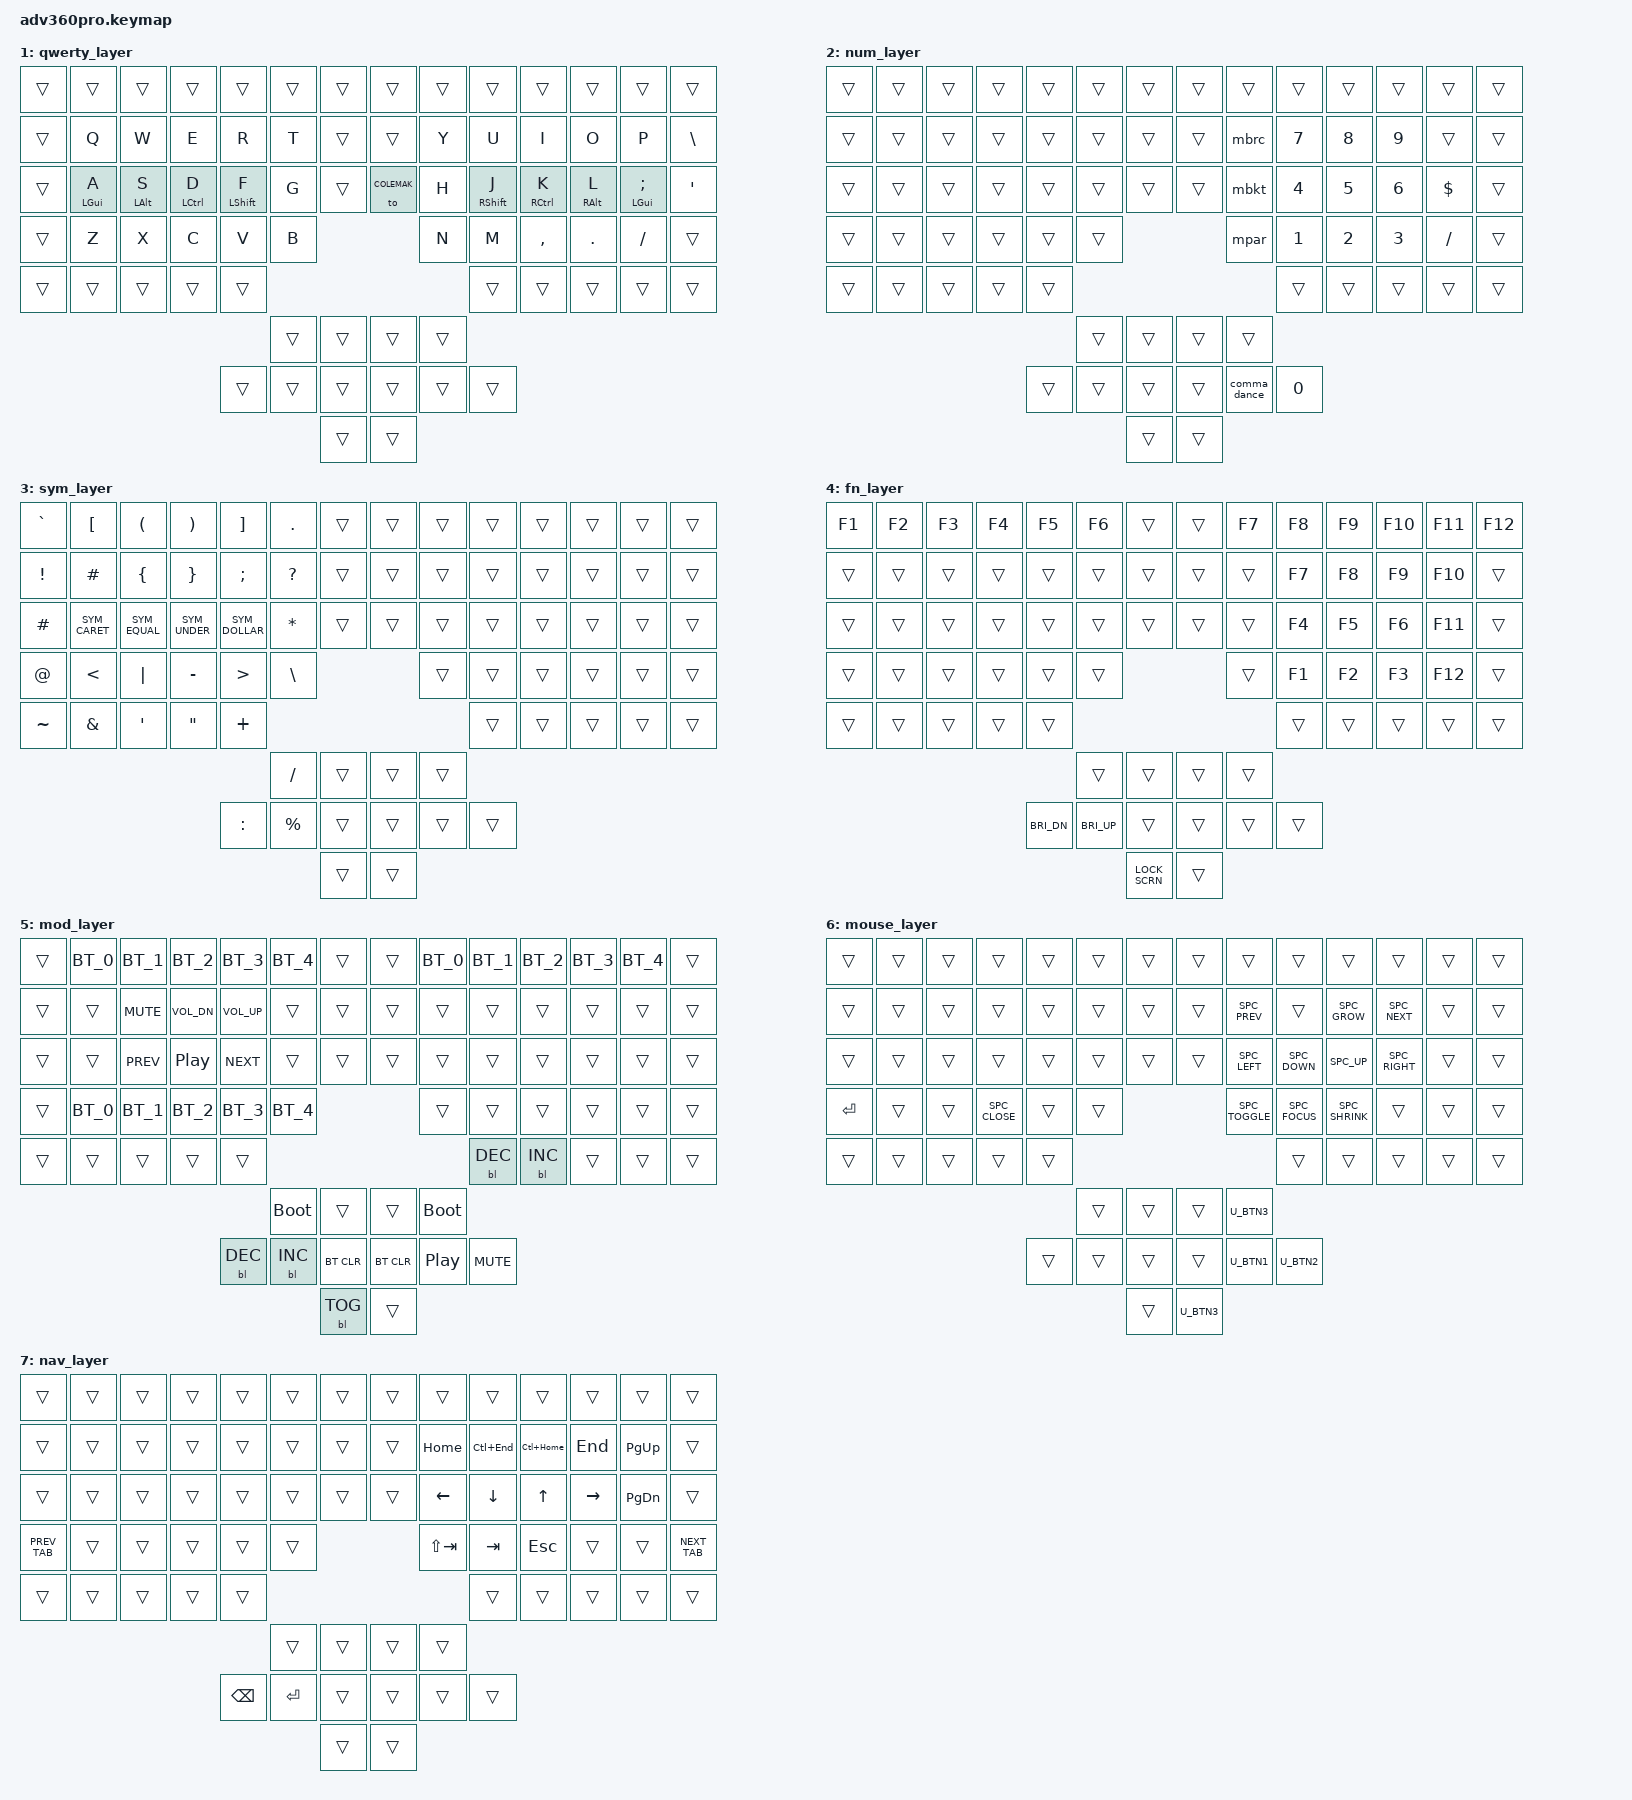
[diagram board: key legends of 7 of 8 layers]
#include <behaviors.dtsi>
#include <dt-bindings/zmk/keys.h>
#include <dt-bindings/zmk/bt.h>
#include <dt-bindings/zmk/outputs.h>
#include <dt-bindings/zmk/rgb.h>
#include <dt-bindings/zmk/backlight.h>

#include "adv360pro_keypos.h"
#include "zmk_helper.h"

/* definitions for mouse layer */
#include "mouse.h"

#define ___ &trans

/* Layer references  */
#define COLEMAK 0
#define QWERTY 1
#define NUM 2
#define SYM 3
#define FN 4
#define MOD 5
#define MS 6
#define NAV 7

/* Global settings */
#include "general.h"

/* Home row mods */
#include "homerow_mods.h"

/* Macros and shortcuts */
#include "custom_behaviors.h"

/ {
    /* remove unused keys from layoua and move thumb cluster to bottom */
    chosen {
        zmk,matrix_transform = &urobs_transform;
    };

    keymap {
        compatible = "zmk,keymap";

// Colemak base
        colemak_layer {
            bindings = <
// ╭─────────────╮╭─────────────┬─────────────┬─────────────┬─────────────┬─────────────╮╭─────────────╮  ╭─────────────╮╭─────────────┬─────────────┬─────────────┬─────────────┬─────────────╮╭─────────────╮
     &kp ESC        &kp N1        &kp N2        &kp N3        &kp N4        &kp N5         &tog NUM         &mo MOD        &kp N6        &kp N7        &kp N8        &kp N9        &kp N0         &kp BSLH
// ╰─────────────╯╰─────────────┴─────────────┴─────────────┴─────────────┴─────────────╯╰─────────────╯  ╰─────────────╯╰─────────────┴─────────────┴─────────────┴─────────────┴─────────────╯╰─────────────╯
// ╭─────────────╮╭─────────────┬─────────────┬─────────────┬─────────────┬─────────────╮╭─────────────╮  ╭─────────────╮╭─────────────┬─────────────┬─────────────┬─────────────┬─────────────╮╭─────────────╮
     &kp GLOBE      &kp Q         &kp W         &kp F         &kp P         &kp B          SWAP_PREV        &tog MS        &kp J         &kp L         &kp U         &kp Y         &kp SEMI        &kp MINUS
// ├─────────────┤├─────────────┼─────────────┼─────────────┼─────────────┼─────────────┤├─────────────┤  ├─────────────┤├─────────────┼─────────────┼─────────────┼─────────────┼─────────────┤├─────────────┤
     &caps_dance    A_LGUI        R_LALT        S_LCTRL       T_LSHFT       &kp G          SWAPPER          &to QWERTY     &lt MOD M     N_RSHFT       E_RCTRL       I_RALT        O_RGUI         &kp SQT
// ├─────────────┤├─────────────┼─────────────┼─────────────┼─────────────┼─────────────┤╰─────────────╯  ╰─────────────╯├─────────────┼─────────────┼─────────────┼─────────────┼─────────────┤├─────────────┤
     &num_word      &kp Z         &kp X         &kp C         &kp D         &kp V                                          &kp K         &kp H         &kp COMMA    &kp DOT      &kp FSLH         &caps_dance
// ╰─────────────╯╰─────────────┴─────────────┴─────────────┴─────────────┴─────────────╯                                ╰─────────────┴─────────────┴─────────────┴─────────────┴─────────────╯╰─────────────╯
// ╭─────────────╮╭─────────────┬─────────────┬─────────────┬─────────────╮                                                            ╭─────────────┬─────────────┬─────────────┬─────────────╮╭─────────────╮
     &mo FN         &num_word     &sk LHYP      &kp C_VOL_DN  &kp C_VOL_UP                                                               &kp C_BRI_DN  &kp C_BRI_UP  &sk RHYP      &caps_dance    &mo MOD
// ╰─────────────╯╰─────────────┴─────────────┴─────────────┴─────────────╯╭─────────────┬─────────────╮  ╭─────────────┬─────────────╮╰─────────────┴─────────────┴─────────────┴─────────────╯╰─────────────╯
                                                                             &lt FN ESC       &caps_dance      &num_word     RET_HYP
//                                                           ╭─────────────┼─────────────┼─────────────┤  ├─────────────┼─────────────┼─────────────╮
                                                               BSPC_NAV      SHFT_NUM      &lt FN HOME      &kp END        &kp TAB       SPC_SYM
//                                                           │             │             ├────────────┤  ├─────────────┤             │            │
                                                                                           &lt MS TAB       &lt FN ESC
//                                                           ╰─────────────┴─────────────┴─────────────╯  ╰─────────────┴─────────────┴─────────────╯

            >;
        };

 // qwerty
        qwerty_layer {
            bindings = <
// ╭─────────────╮╭─────────────┬─────────────┬─────────────┬─────────────┬─────────────╮╭─────────────╮  ╭─────────────╮╭─────────────┬─────────────┬─────────────┬─────────────┬─────────────╮╭─────────────╮
     ___            ___           ___           ___           ___           ___            ___              ___            ___           ___           ___           ___           ___            ___
// ╰─────────────╯╰─────────────┴─────────────┴─────────────┴─────────────┴─────────────╯╰─────────────╯  ╰─────────────╯╰─────────────┴─────────────┴─────────────┴─────────────┴─────────────╯╰─────────────╯
// ╭─────────────╮╭─────────────┬─────────────┬─────────────┬─────────────┬─────────────╮╭─────────────╮  ╭─────────────╮╭─────────────┬─────────────┬─────────────┬─────────────┬─────────────╮╭─────────────╮
     ___            &kp Q         &kp W         &kp E         &kp R         &kp T          ___              ___            &kp Y         &kp U         &kp I         &kp O         &kp P          &kp BSLH
// ├─────────────┤├─────────────┼─────────────┼─────────────┼─────────────┼─────────────┤├─────────────┤  ├─────────────┤├─────────────┼─────────────┼─────────────┼─────────────┼─────────────┤├─────────────┤
     ___            &hml LGUI A  &hml LALT S  &hml LCTRL D  &hml LSHFT F  &kp G          ___              &to COLEMAK    &kp H         &hmr RSHFT J  &hmr RCTRL K   &hmr RALT L  &hmr LGUI SEMI &kp SQT
// ├─────────────┤├─────────────┼─────────────┼─────────────┼─────────────┼─────────────┤╰─────────────╯  ╰─────────────╯├─────────────┼─────────────┼─────────────┼─────────────┼─────────────┤├─────────────┤
     ___            &kp Z         &kp X         &kp C         &kp V         &kp B                                          &kp N         &kp M         &kp COMMA     &kp DOT       &kp FSLH       ___
// ╰─────────────╯╰─────────────┴─────────────┴─────────────┴─────────────┴─────────────╯                                ╰─────────────┴─────────────┴─────────────┴─────────────┴─────────────╯╰─────────────╯
// ╭─────────────╮╭─────────────┬─────────────┬─────────────┬─────────────╮                                                            ╭─────────────┬─────────────┬─────────────┬─────────────╮╭─────────────╮
     ___            ___           ___           ___           ___                                                                        ___           ___           ___           ___            ___
// ╰─────────────╯╰─────────────┴─────────────┴─────────────┴─────────────╯╭─────────────┬─────────────╮  ╭─────────────┬─────────────╮╰─────────────┴─────────────┴─────────────┴─────────────╯╰─────────────╯
                                                                             ___           ___              ___           ___
//                                                           ╭─────────────┼─────────────┼─────────────┤  ├─────────────┼─────────────┼─────────────╮
                                                               ___           ___           ___              ___           ___            ___
//                                                           │             │             ├─────────────┤  ├─────────────┤             │             │
                                                                                           ___              ___
//                                                           ╰─────────────┴─────────────┴─────────────╯  ╰─────────────┴─────────────┴─────────────╯
            >;
        };


        num_layer {
            bindings = <
// ╭─────────────╮╭─────────────┬─────────────┬─────────────┬─────────────┬─────────────╮╭─────────────╮  ╭─────────────╮╭─────────────┬─────────────┬─────────────┬─────────────┬─────────────╮╭─────────────╮
     ___            ___           ___           ___           ___           ___             ___              ___            ___          ___           ___           ___           ___            ___
// ╰─────────────╯╰─────────────┴─────────────┴─────────────┴─────────────┴─────────────╯╰─────────────╯  ╰─────────────╯╰─────────────┴─────────────┴─────────────┴─────────────┴─────────────╯╰─────────────╯
// ╭─────────────╮╭─────────────┬─────────────┬─────────────┬─────────────┬─────────────╮╭─────────────╮  ╭─────────────╮╭─────────────┬─────────────┬─────────────┬─────────────┬─────────────╮╭─────────────╮
     ___            ___           ___           ___           ___           ___             ___              ___            &mbrc        &kp N7        &kp N8        &kp N9        ___            ___
// ├─────────────┤├─────────────┼─────────────┼─────────────┼─────────────┼─────────────┤├─────────────┤  ├─────────────┤├─────────────┼─────────────┼─────────────┼─────────────┼─────────────┤├─────────────┤
     ___            ___           ___           ___           ___           ___              ___             ___            &mbkt        &kp N4        &kp N5        &kp N6        &kp DOLLAR     ___
// ├─────────────┤├─────────────┼─────────────┼─────────────┼─────────────┼─────────────┤╰─────────────╯  ╰─────────────╯├─────────────┼─────────────┼─────────────┼─────────────┼─────────────┤├─────────────┤
     ___            ___           ___           ___           ___           ___                                             &mpar        &kp N1        &kp N2        &kp N3        &kp FSLH       ___
// ╰─────────────╯╰─────────────┴─────────────┴─────────────┴─────────────┴─────────────╯                                ╰─────────────┴─────────────┴─────────────┴─────────────┴─────────────╯╰─────────────╯
// ╭─────────────╮╭─────────────┬─────────────┬─────────────┬─────────────╮                                                            ╭─────────────┬─────────────┬─────────────┬─────────────╮╭─────────────╮
     ___            ___           ___           ___           ___                                                                        ___           ___           ___           ___            ___
// ╰─────────────╯╰─────────────┴─────────────┴─────────────┴─────────────╯╭─────────────┬─────────────╮  ╭─────────────┬─────────────╮╰─────────────┴─────────────┴─────────────┴─────────────╯╰─────────────╯
                                                                             ___           ___              ___           ___
//                                                           ╭─────────────┼─────────────┼─────────────┤  ├─────────────┼─────────────┼─────────────╮
                                                               ___           ___           ___              ___           &comma_dance  &kp N0
//                                                           │             │             ├─────────────┤  ├─────────────┤             │             │
                                                                                           ___              ___
//                                                           ╰─────────────┴─────────────┴─────────────╯  ╰─────────────┴─────────────┴─────────────╯
            >;
        };

        sym_layer {
          bindings = <
// ╭─────────────╮╭─────────────┬─────────────┬─────────────┬─────────────┬─────────────╮╭─────────────╮  ╭─────────────╮╭─────────────┬─────────────┬─────────────┬─────────────┬─────────────╮╭─────────────╮
     &kp GRAVE      &kp LBKT      &kp LPAR        &kp RPAR    &kp RBKT       &kp DOT       ___              ___            ___           ___           ___           ___           ___            ___
// ╰─────────────╯╰─────────────┴─────────────┴─────────────┴─────────────┴─────────────╯╰─────────────╯  ╰─────────────╯╰─────────────┴─────────────┴─────────────┴─────────────┴─────────────╯╰─────────────╯
// ╭─────────────╮╭─────────────┬─────────────┬─────────────┬─────────────┬─────────────╮╭─────────────╮  ╭─────────────╮╭─────────────┬─────────────┬─────────────┬─────────────┬─────────────╮╭─────────────╮
     &kp EXCL       &kp HASH      &kp LBRC        &kp RBRC    &kp SEMICOLON  &kp QMARK     ___              ___            ___           ___           ___           ___           ___            ___
// ├─────────────┤├─────────────┼─────────────┼─────────────┼─────────────┼─────────────┤├─────────────┤  ├─────────────┤├─────────────┼─────────────┼─────────────┼─────────────┼─────────────┤├─────────────┤
     &kp HASH       SYM_CARET     SYM_EQUAL     SYM_UNDER     SYM_DOLLAR     &kp STAR      ___              ___            ___           ___           ___           ___           ___            ___
// ├─────────────┤├─────────────┼─────────────┼─────────────┼─────────────┼─────────────┤╰─────────────╯  ╰─────────────╯├─────────────┼─────────────┼─────────────┼─────────────┼─────────────┤├─────────────┤
     &kp AT         &kp LT        &kp PIPE      &kp MINUS     &kp GT        &kp BSLH                                       ___           ___           ___           ___           ___            ___
// ╰─────────────╯╰─────────────┴─────────────┴─────────────┴─────────────┴─────────────╯                                ╰─────────────┴─────────────┴─────────────┴─────────────┴─────────────╯╰─────────────╯
// ╭─────────────╮╭─────────────┬─────────────┬─────────────┬─────────────╮                                                            ╭─────────────┬─────────────┬─────────────┬─────────────╮╭─────────────╮
     &kp TILDE      &kp AMPERSAND &kp SQT       &kp DQT       &kp PLUS                                                                   ___           ___           ___           ___            ___
// ╰─────────────╯╰─────────────┴─────────────┴─────────────┴─────────────╯╭─────────────┬─────────────╮  ╭─────────────┬─────────────╮╰─────────────┴─────────────┴─────────────┴─────────────╯╰─────────────╯
                                                                             &kp FSLH         ___              ___           ___
//                                                           ╭─────────────┼─────────────┼─────────────┤  ├─────────────┼─────────────┼─────────────╮
                                                               &kp COLON     &kp PERCENT      ___              ___             ___       ___ 
//                                                           │             │             ├─────────────┤  ├─────────────┤             │             │
                                                                                              ___              ___
//                                                           ╰─────────────┴─────────────┴─────────────╯  ╰─────────────┴─────────────┴─────────────╯
            >;
        };

        fn_layer {
            bindings = <
// ╭─────────────╮╭─────────────┬─────────────┬─────────────┬─────────────┬─────────────╮╭─────────────╮  ╭─────────────╮╭─────────────┬─────────────┬─────────────┬─────────────┬─────────────╮╭─────────────╮
     &kp F1         &kp F2        &kp F3        &kp F4        &kp F5        &kp F6         ___              ___            &kp F7        &kp F8        &kp F9        &kp F10       &kp F11        &kp F12
// ╰─────────────╯╰─────────────┴─────────────┴─────────────┴─────────────┴─────────────╯╰─────────────╯  ╰─────────────╯╰─────────────┴─────────────┴─────────────┴─────────────┴─────────────╯╰─────────────╯
// ╭─────────────╮╭─────────────┬─────────────┬─────────────┬─────────────┬─────────────╮╭─────────────╮  ╭─────────────╮╭─────────────┬─────────────┬─────────────┬─────────────┬─────────────╮╭─────────────╮
     ___            ___           ___           ___           ___           ___            ___              ___            ___           &kp F7        &kp F8        &kp F9        &kp F10        ___
// ├─────────────┤├─────────────┼─────────────┼─────────────┼─────────────┼─────────────┤├─────────────┤  ├─────────────┤├─────────────┼─────────────┼─────────────┼─────────────┼─────────────┤├─────────────┤
     ___            ___           ___           ___           ___           ___            ___              ___            ___           &kp F4        &kp F5        &kp F6        &kp F11        ___
// ├─────────────┤├─────────────┼─────────────┼─────────────┼─────────────┼─────────────┤╰─────────────╯  ╰─────────────╯├─────────────┼─────────────┼─────────────┼─────────────┼─────────────┤├─────────────┤
     ___            ___           ___           ___           ___           ___                                            ___           &kp F1        &kp F2        &kp F3        &kp F12        ___
// ╰─────────────╯╰─────────────┴─────────────┴─────────────┴─────────────┴─────────────╯                                ╰─────────────┴─────────────┴─────────────┴─────────────┴─────────────╯╰─────────────╯
// ╭─────────────╮╭─────────────┬─────────────┬─────────────┬─────────────╮                                                            ╭─────────────┬─────────────┬─────────────┬─────────────╮╭─────────────╮
     ___            ___           ___           ___           ___                                                                        ___           ___           ___           ___            ___
// ╰─────────────╯╰─────────────┴─────────────┴─────────────┴─────────────╯╭─────────────┬─────────────╮  ╭─────────────┬─────────────╮╰─────────────┴─────────────┴─────────────┴─────────────╯╰─────────────╯
                                                                             ___           ___              ___           ___
//                                                           ╭─────────────┼─────────────┼─────────────┤  ├─────────────┼─────────────┼─────────────╮
                                                               &kp C_BRI_DN  &kp C_BRI_UP  ___              ___           ___           ___
//                                                           │             │             ├─────────────┤  ├─────────────┤             │             │
                                                                                           LOCK_SCRN        ___
//                                                           ╰─────────────┴─────────────┴─────────────╯  ╰─────────────┴─────────────┴─────────────╯
            >;
        };

        mod_layer {
            bindings = <
// ╭─────────────╮╭─────────────┬─────────────┬─────────────┬─────────────┬─────────────╮╭─────────────╮  ╭─────────────╮╭─────────────┬─────────────┬─────────────┬─────────────┬─────────────╮╭─────────────╮
     ___            BT_0          BT_1          BT_2          BT_3          BT_4           ___              ___            BT_0          BT_1          BT_2          BT_3          BT_4           ___
// ╰─────────────╯╰─────────────┴─────────────┴─────────────┴─────────────┴─────────────╯╰─────────────╯  ╰─────────────╯╰─────────────┴─────────────┴─────────────┴─────────────┴─────────────╯╰─────────────╯
// ╭─────────────╮╭─────────────┬─────────────┬─────────────┬─────────────┬─────────────╮╭─────────────╮  ╭─────────────╮╭─────────────┬─────────────┬─────────────┬─────────────┬─────────────╮╭─────────────╮
     ___            ___           &kp C_MUTE    &kp C_VOL_DN  &kp C_VOL_UP  ___            ___              ___            ___           ___           ___           ___           ___            ___
// ├─────────────┤├─────────────┼─────────────┼─────────────┼─────────────┼─────────────┤├─────────────┤  ├─────────────┤├─────────────┼─────────────┼─────────────┼─────────────┼─────────────┤├─────────────┤
     ___            ___           &kp C_PREV    &kp C_PP      &kp C_NEXT    ___            ___              ___            ___           ___           ___           ___           ___            ___
// ├─────────────┤├─────────────┼─────────────┼─────────────┼─────────────┼─────────────┤╰─────────────╯  ╰─────────────╯├─────────────┼─────────────┼─────────────┼─────────────┼─────────────┤├─────────────┤
     ___            BT_0          BT_1          BT_2          BT_3          BT_4                                           ___           ___           ___           ___           ___            ___
// ╰─────────────╯╰─────────────┴─────────────┴─────────────┴─────────────┴─────────────╯                                ╰─────────────┴─────────────┴─────────────┴─────────────┴─────────────╯╰─────────────╯
// ╭─────────────╮╭─────────────┬─────────────┬─────────────┬─────────────╮                                                            ╭─────────────┬─────────────┬─────────────┬─────────────╮╭─────────────╮
     ___            ___           ___           ___           ___                                                                        &bl BL_DEC    &bl BL_INC    ___           ___            ___
// ╰─────────────╯╰─────────────┴─────────────┴─────────────┴─────────────╯╭─────────────┬─────────────╮  ╭─────────────┬─────────────╮╰─────────────┴─────────────┴─────────────┴─────────────╯╰─────────────╯
                                                                             &bootloader   ___              ___           &bootloader
//                                                           ╭─────────────┼─────────────┼─────────────┤  ├─────────────┼─────────────┼─────────────╮
                                                               &bl BL_DEC    &bl BL_INC    &bt BT_CLR       &bt BT_CLR    &kp C_PP      &kp C_MUTE
//                                                           │             │             ├─────────────┤  ├─────────────┤             │             │
                                                                                           &bl BL_TOG      ___
//                                                           ╰─────────────┴─────────────┴─────────────╯  ╰─────────────┴─────────────┴─────────────╯
            >;
        };

        mouse_layer {
            bindings = <
// ╭─────────────╮╭─────────────┬─────────────┬─────────────┬─────────────┬─────────────╮╭─────────────╮  ╭─────────────╮╭─────────────┬─────────────┬─────────────┬─────────────┬─────────────╮╭─────────────╮
     ___            ___           ___           ___           ___           ___            ___              ___            ___           ___           ___           ___           ___            ___
// ╰─────────────╯╰─────────────┴─────────────┴─────────────┴─────────────┴─────────────╯╰─────────────╯  ╰─────────────╯╰─────────────┴─────────────┴─────────────┴─────────────┴─────────────╯╰─────────────╯
// ╭─────────────╮╭─────────────┬─────────────┬─────────────┬─────────────┬─────────────╮╭─────────────╮  ╭─────────────╮╭─────────────┬─────────────┬─────────────┬─────────────┬─────────────╮╭─────────────╮
     ___            ___           ___           ___           ___           ___            ___              ___            SPC_PREV      ___           SPC_GROW      SPC_NEXT      ___            ___
// ├─────────────┤├─────────────┼─────────────┼─────────────┼─────────────┼─────────────┤├─────────────┤  ├─────────────┤├─────────────┼─────────────┼─────────────┼─────────────┼─────────────┤├─────────────┤
     ___            ___           ___           ___           ___           ___            ___              ___            SPC_LEFT      SPC_DOWN      SPC_UP        SPC_RIGHT     ___            ___
// ├─────────────┤├─────────────┼─────────────┼─────────────┼─────────────┼─────────────┤╰─────────────╯  ╰─────────────╯├─────────────┼─────────────┼─────────────┼─────────────┼─────────────┤├─────────────┤
     &kp ENTER      ___           ___           SPC_CLOSE     ___           ___                                          SPC_TOGGLE      SPC_FOCUS     SPC_SHRINK    ___           ___            ___
// ╰─────────────╯╰─────────────┴─────────────┴─────────────┴─────────────┴─────────────╯                                ╰─────────────┴─────────────┴─────────────┴─────────────┴─────────────╯╰─────────────╯
// ╭─────────────╮╭─────────────┬─────────────┬─────────────┬─────────────╮                                                            ╭─────────────┬─────────────┬─────────────┬─────────────╮╭─────────────╮
     ___            ___           ___           ___           ___                                                                        ___           ___           ___           ___            ___
// ╰─────────────╯╰─────────────┴─────────────┴─────────────┴─────────────╯╭─────────────┬─────────────╮  ╭─────────────┬─────────────╮╰─────────────┴─────────────┴─────────────┴─────────────╯╰─────────────╯
                                                                             ___           ___              ___            U_BTN3
//                                                           ╭─────────────┼─────────────┼─────────────┤  ├─────────────┼─────────────┼─────────────╮
                                                               ___           ___           ___              ___            U_BTN1        U_BTN2
//                                                           │             │             ├─────────────┤  ├─────────────┤             │             │
                                                                                           ___              U_BTN3
//                                                           ╰─────────────┴─────────────┴─────────────╯  ╰─────────────┴─────────────┴─────────────╯
            >;
        };

        nav_layer {
            bindings = <
// ╭─────────────╮╭─────────────┬─────────────┬─────────────┬─────────────┬─────────────╮╭─────────────╮  ╭─────────────╮╭─────────────┬─────────────┬─────────────┬─────────────┬─────────────╮╭─────────────╮
     ___            ___           ___           ___           ___           ___            ___              ___            ___           ___           ___           ___           ___            ___
// ╰─────────────╯╰─────────────┴─────────────┴─────────────┴─────────────┴─────────────╯╰─────────────╯  ╰─────────────╯╰─────────────┴─────────────┴─────────────┴─────────────┴─────────────╯╰─────────────╯
// ╭─────────────╮╭─────────────┬─────────────┬─────────────┬─────────────┬─────────────╮╭─────────────╮  ╭─────────────╮╭─────────────┬─────────────┬─────────────┬─────────────┬─────────────╮╭─────────────╮
     ___            ___           ___           ___           ___           ___            ___              ___           &kp HOME   &kp LC(END)   &kp LC(HOME)    &kp END      &kp PG_UP         ___
// ├─────────────┤├─────────────┼─────────────┼─────────────┼─────────────┼─────────────┤├─────────────┤  ├─────────────┤├─────────────┼─────────────┼─────────────┼─────────────┼─────────────┤├─────────────┤
     ___            ___           ___           ___           ___           ___            ___              ___            &kp LEFT      &kp DOWN       &kp UP    &kp RIGHT     &kp PG_DN         ___
// ├─────────────┤├─────────────┼─────────────┼─────────────┼─────────────┼─────────────┤╰─────────────╯  ╰─────────────╯├─────────────┼─────────────┼─────────────┼─────────────┼─────────────┤├─────────────┤
     PREV_TAB       ___           ___           ___           ___           ___                                           &kp LS(TAB)     &kp TAB      &kp ESC       ___           ___            NEXT_TAB
// ╰─────────────╯╰─────────────┴─────────────┴─────────────┴─────────────┴─────────────╯                                ╰─────────────┴─────────────┴─────────────┴─────────────┴─────────────╯╰─────────────╯
// ╭─────────────╮╭─────────────┬─────────────┬─────────────┬─────────────╮                                                            ╭─────────────┬─────────────┬─────────────┬─────────────╮╭─────────────╮
     ___            ___           ___           ___           ___                                                                        ___           ___           ___           ___            ___
// ╰─────────────╯╰─────────────┴─────────────┴─────────────┴─────────────╯╭─────────────┬─────────────╮  ╭─────────────┬─────────────╮╰─────────────┴─────────────┴─────────────┴─────────────╯╰─────────────╯
                                                                             ___           ___              ___           ___
//                                                           ╭─────────────┼─────────────┼─────────────┤  ├─────────────┼─────────────┼─────────────╮
                                                               &kp BSPC      &kp ENTER     ___              ___           ___           ___
//                                                           │             │             ├─────────────┤  ├─────────────┤             │             │
                                                                                           ___              ___
//                                                           ╰─────────────┴─────────────┴─────────────╯  ╰─────────────┴─────────────┴─────────────╯
            >;
        };

    };



};
